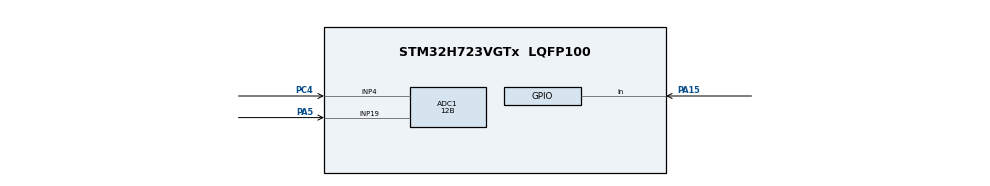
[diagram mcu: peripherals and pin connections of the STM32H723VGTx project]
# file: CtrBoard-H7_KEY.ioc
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ADC1.Channel-2\#ChannelRegularConversion=ADC_CHANNEL_4
ADC1.Channel-3\#ChannelRegularConversion=ADC_CHANNEL_19
ADC1.ClockPrescaler=ADC_CLOCK_ASYNC_DIV16
ADC1.ContinuousConvMode=ENABLE
ADC1.ConversionDataManagement=ADC_CONVERSIONDATA_DMA_CIRCULAR
ADC1.EOCSelection=ADC_EOC_SINGLE_CONV
ADC1.NbrOfConversion=2
ADC1.NbrOfConversionFlag=1
ADC1.OffsetNumber-2\#ChannelRegularConversion=ADC_OFFSET_NONE
ADC1.OffsetNumber-3\#ChannelRegularConversion=ADC_OFFSET_NONE
ADC1.OffsetSignedSaturation-2\#ChannelRegularConversion=DISABLE
ADC1.OffsetSignedSaturation-3\#ChannelRegularConversion=DISABLE
ADC1.Overrun=ADC_OVR_DATA_PRESERVED
ADC1.Rank-2\#ChannelRegularConversion=1
ADC1.Rank-3\#ChannelRegularConversion=2
ADC1.Resolution=ADC_RESOLUTION_12B
ADC1.SamplingTime-2\#ChannelRegularConversion=ADC_SAMPLETIME_32CYCLES_5
ADC1.SamplingTime-3\#ChannelRegularConversion=ADC_SAMPLETIME_32CYCLES_5
ADC1.master=1
CORTEX_M7.CPU_DCache=Disabled
CORTEX_M7.CPU_ICache=Disabled
Dma.ADC1.0.Direction=DMA_PERIPH_TO_MEMORY
Dma.ADC1.0.EventEnable=DISABLE
Dma.ADC1.0.FIFOMode=DMA_FIFOMODE_DISABLE
Dma.ADC1.0.Instance=DMA1_Stream0
Dma.ADC1.0.MemDataAlignment=DMA_MDATAALIGN_HALFWORD
Dma.ADC1.0.MemInc=DMA_MINC_ENABLE
Dma.ADC1.0.Mode=DMA_CIRCULAR
Dma.ADC1.0.PeriphDataAlignment=DMA_PDATAALIGN_HALFWORD
Dma.ADC1.0.PeriphInc=DMA_PINC_DISABLE
Dma.ADC1.0.Polarity=HAL_DMAMUX_REQ_GEN_RISING
Dma.ADC1.0.Priority=DMA_PRIORITY_LOW
Dma.ADC1.0.RequestNumber=1
Dma.ADC1.0.SignalID=NONE
Dma.ADC1.0.SyncEnable=DISABLE
Dma.ADC1.0.SyncPolarity=HAL_DMAMUX_SYNC_NO_EVENT
Dma.ADC1.0.SyncRequestNumber=1
Dma.ADC1.0.SyncSignalID=NONE
Dma.Request0=ADC1
Mcu.Family=STM32H7
Mcu.Name=STM32H723VGTx
Mcu.Package=LQFP100
NVIC.DMA1_Stream0_IRQn=true\:0\:0\:false\:false\:true\:false\:true\:true
NVIC.PriorityGroup=NVIC_PRIORITYGROUP_4
PA13(JTMS/SWDIO).Mode=Serial_Wire
PA13(JTMS/SWDIO).Signal=DEBUG_JTMS-SWDIO
PA14(JTCK/SWCLK).Mode=Serial_Wire
PA14(JTCK/SWCLK).Signal=DEBUG_JTCK-SWCLK
PA15(JTDI).Signal=GPIO_Input
PA5.Signal=ADCx_INP19
PC4.Signal=ADCx_INP4
PH0-OSC_IN.Mode=HSE-External-Oscillator
PH0-OSC_IN.Signal=RCC_OSC_IN
PH1-OSC_OUT.Mode=HSE-External-Oscillator
PH1-OSC_OUT.Signal=RCC_OSC_OUT
ProjectManager.HeapSize=0x200
ProjectManager.StackSize=0x400
ProjectManager.TargetToolchain=MDK-ARM V5.32
RCC.ADCFreq_Value=96000000
RCC.APB1Freq_Value=120000000
RCC.APB2Freq_Value=120000000
RCC.APB3Freq_Value=120000000
RCC.APB4Freq_Value=120000000
RCC.CortexFreq_Value=480000000
RCC.D1PPRE=RCC_APB3_DIV2
RCC.D2PPRE1=RCC_APB1_DIV2
RCC.D2PPRE2=RCC_APB2_DIV2
RCC.D3PPRE=RCC_APB4_DIV2
RCC.DIVM1=2
RCC.DIVM2=2
RCC.DIVN1=40
RCC.DIVN2=16
RCC.DIVP1=1
RCC.HCLKFreq_Value=240000000
RCC.HPRE=RCC_HCLK_DIV2
RCC.HSE_VALUE=24000000
RCC.PLLFRACN=0
RCC.PLLSourceVirtual=RCC_PLLSOURCE_HSE
RCC.SYSCLKFreq_VALUE=480000000
RCC.SYSCLKSource=RCC_SYSCLKSOURCE_PLLCLK
RCC.USBFreq_Value=240000000
SH.ADCx_INP19.0=ADC1_INP19,IN19-Single-Ended
SH.ADCx_INP4.0=ADC1_INP4,IN4-Single-Ended
board=custom

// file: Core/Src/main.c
/* USER CODE BEGIN Header */
/**
  ******************************************************************************
  * @file           : main.c
  * @brief          : Main program body
  ******************************************************************************
  * @attention
  *
  * Copyright (c) 2024 STMicroelectronics.
  * All rights reserved.
  *
  * This software is licensed under terms that can be found in the LICENSE file
  * in the root directory of this software component.
  * If no LICENSE file comes with this software, it is provided AS-IS.
  *
  ******************************************************************************
  */
/* USER CODE END Header */
#include "main.h"
#include "adc.h"
#include "dma.h"
#include "gpio.h"

/* USER CODE BEGIN Includes */
#include "adc_modlue.h"
#include "key_driver.h"
#include "key_bsp.h"
/* USER CODE END Includes */

void SystemClock_Config(void);

/* USER CODE BEGIN 0 */
uint16_t adc_val[2];
float vbus;
/* USER CODE END 0 */

int main(void)
{

  /* MCU Configuration--------------------------------------------------------*/

  /* Reset of all peripherals, Initializes the Flash interface and the Systick. */
  HAL_Init();

  /* Configure the system clock */
  SystemClock_Config();

  /* Initialize all configured peripherals */
  MX_GPIO_Init();
  MX_DMA_Init();
  MX_ADC1_Init();
  /* USER CODE BEGIN 2 */
	HAL_ADCEx_Calibration_Start(&hadc1, ADC_CALIB_OFFSET, ADC_SINGLE_ENDED);
	HAL_ADC_Start_DMA(&hadc1, (uint32_t *)adc_val,2);

	key_driver_init();	// 按键数组初始化
  /* USER CODE END 2 */

  /* Infinite loop */
  /* USER CODE BEGIN WHILE */
  while (1)
  {
		get_key_adc();
		key_process();
		vbus = (adc_val[0]*3.3f/4096)*11.0f;
		HAL_Delay(1);
    /* USER CODE END WHILE */

  }
}

void SystemClock_Config(void)
{
  RCC_OscInitTypeDef RCC_OscInitStruct = {0};
  RCC_ClkInitTypeDef RCC_ClkInitStruct = {0};

  /** Supply configuration update enable
  */
  HAL_PWREx_ConfigSupply(PWR_LDO_SUPPLY);

  /** Configure the main internal regulator output voltage
  */
  __HAL_PWR_VOLTAGESCALING_CONFIG(PWR_REGULATOR_VOLTAGE_SCALE0);

  while(!__HAL_PWR_GET_FLAG(PWR_FLAG_VOSRDY)) {}

  /** Initializes the RCC Oscillators according to the specified parameters
  * in the RCC_OscInitTypeDef structure.
  */
  RCC_OscInitStruct.OscillatorType = RCC_OSCILLATORTYPE_HSE;
  RCC_OscInitStruct.HSEState = RCC_HSE_ON;
  RCC_OscInitStruct.PLL.PLLState = RCC_PLL_ON;
  RCC_OscInitStruct.PLL.PLLSource = RCC_PLLSOURCE_HSE;
  RCC_OscInitStruct.PLL.PLLM = 2;
  RCC_OscInitStruct.PLL.PLLN = 40;
  RCC_OscInitStruct.PLL.PLLP = 1;
  RCC_OscInitStruct.PLL.PLLQ = 2;
  RCC_OscInitStruct.PLL.PLLR = 2;
  RCC_OscInitStruct.PLL.PLLRGE = RCC_PLL1VCIRANGE_3;
  RCC_OscInitStruct.PLL.PLLVCOSEL = RCC_PLL1VCOWIDE;
  RCC_OscInitStruct.PLL.PLLFRACN = 0;
  if (HAL_RCC_OscConfig(&RCC_OscInitStruct) != HAL_OK)
  {
    Error_Handler();
  }

  /** Initializes the CPU, AHB and APB buses clocks
  */
  RCC_ClkInitStruct.ClockType = RCC_CLOCKTYPE_HCLK|RCC_CLOCKTYPE_SYSCLK
                              |RCC_CLOCKTYPE_PCLK1|RCC_CLOCKTYPE_PCLK2
                              |RCC_CLOCKTYPE_D3PCLK1|RCC_CLOCKTYPE_D1PCLK1;
  RCC_ClkInitStruct.SYSCLKSource = RCC_SYSCLKSOURCE_PLLCLK;
  RCC_ClkInitStruct.SYSCLKDivider = RCC_SYSCLK_DIV1;
  RCC_ClkInitStruct.AHBCLKDivider = RCC_HCLK_DIV2;
  RCC_ClkInitStruct.APB3CLKDivider = RCC_APB3_DIV2;
  RCC_ClkInitStruct.APB1CLKDivider = RCC_APB1_DIV2;
  RCC_ClkInitStruct.APB2CLKDivider = RCC_APB2_DIV2;
  RCC_ClkInitStruct.APB4CLKDivider = RCC_APB4_DIV2;

  if (HAL_RCC_ClockConfig(&RCC_ClkInitStruct, FLASH_LATENCY_3) != HAL_OK)
  {
    Error_Handler();
  }
}

void Error_Handler(void)
{
  __disable_irq();
  while (1)
  {
  }
}
